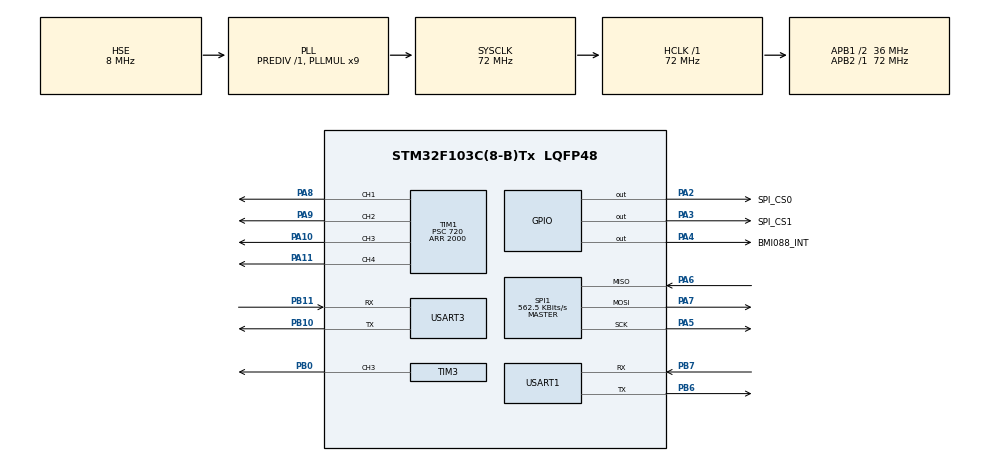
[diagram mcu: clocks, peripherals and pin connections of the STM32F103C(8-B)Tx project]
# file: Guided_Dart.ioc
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Dma.Request0=USART1_RX
Dma.Request1=USART1_TX
Dma.Request2=USART3_RX
Dma.Request3=USART3_TX
Dma.USART1_RX.0.Direction=DMA_PERIPH_TO_MEMORY
Dma.USART1_RX.0.Instance=DMA1_Channel5
Dma.USART1_RX.0.MemDataAlignment=DMA_MDATAALIGN_BYTE
Dma.USART1_RX.0.MemInc=DMA_MINC_ENABLE
Dma.USART1_RX.0.Mode=DMA_NORMAL
Dma.USART1_RX.0.PeriphDataAlignment=DMA_PDATAALIGN_BYTE
Dma.USART1_RX.0.PeriphInc=DMA_PINC_DISABLE
Dma.USART1_RX.0.Priority=DMA_PRIORITY_LOW
Dma.USART1_TX.1.Direction=DMA_MEMORY_TO_PERIPH
Dma.USART1_TX.1.Instance=DMA1_Channel4
Dma.USART1_TX.1.MemDataAlignment=DMA_MDATAALIGN_BYTE
Dma.USART1_TX.1.MemInc=DMA_MINC_ENABLE
Dma.USART1_TX.1.Mode=DMA_NORMAL
Dma.USART1_TX.1.PeriphDataAlignment=DMA_PDATAALIGN_BYTE
Dma.USART1_TX.1.PeriphInc=DMA_PINC_DISABLE
Dma.USART1_TX.1.Priority=DMA_PRIORITY_LOW
Dma.USART3_RX.2.Direction=DMA_PERIPH_TO_MEMORY
Dma.USART3_RX.2.Instance=DMA1_Channel3
Dma.USART3_RX.2.MemDataAlignment=DMA_MDATAALIGN_BYTE
Dma.USART3_RX.2.MemInc=DMA_MINC_ENABLE
Dma.USART3_RX.2.Mode=DMA_NORMAL
Dma.USART3_RX.2.PeriphDataAlignment=DMA_PDATAALIGN_BYTE
Dma.USART3_RX.2.PeriphInc=DMA_PINC_DISABLE
Dma.USART3_RX.2.Priority=DMA_PRIORITY_LOW
Dma.USART3_TX.3.Direction=DMA_MEMORY_TO_PERIPH
Dma.USART3_TX.3.Instance=DMA1_Channel2
Dma.USART3_TX.3.MemDataAlignment=DMA_MDATAALIGN_BYTE
Dma.USART3_TX.3.MemInc=DMA_MINC_ENABLE
Dma.USART3_TX.3.Mode=DMA_NORMAL
Dma.USART3_TX.3.PeriphDataAlignment=DMA_PDATAALIGN_BYTE
Dma.USART3_TX.3.PeriphInc=DMA_PINC_DISABLE
Dma.USART3_TX.3.Priority=DMA_PRIORITY_LOW
Mcu.Family=STM32F1
Mcu.Name=STM32F103C(8-B)Tx
Mcu.Package=LQFP48
NVIC.DMA1_Channel2_IRQn=true\:0\:0\:false\:false\:true\:false\:true\:true
NVIC.DMA1_Channel3_IRQn=true\:0\:0\:false\:false\:true\:false\:true\:true
NVIC.DMA1_Channel4_IRQn=true\:0\:0\:false\:false\:true\:false\:true\:true
NVIC.DMA1_Channel5_IRQn=true\:0\:0\:false\:false\:true\:false\:true\:true
NVIC.PriorityGroup=NVIC_PRIORITYGROUP_4
NVIC.TIM2_IRQn=true\:0\:0\:false\:false\:true\:true\:true\:true
NVIC.USART1_IRQn=true\:1\:0\:true\:false\:true\:true\:true\:true
NVIC.USART3_IRQn=true\:1\:0\:true\:false\:true\:true\:true\:true
PA10.Signal=S_TIM1_CH3
PA11.Signal=S_TIM1_CH4
PA13.Mode=Serial_Wire
PA13.Signal=SYS_JTMS-SWDIO
PA14.Mode=Serial_Wire
PA14.Signal=SYS_JTCK-SWCLK
PA2.GPIO_Label=SPI_CS0
PA2.Signal=GPIO_Output
PA3.GPIO_Label=SPI_CS1
PA3.Signal=GPIO_Output
PA4.GPIO_Label=BMI088_INT
PA4.Signal=GPIO_Output
PA5.Mode=Full_Duplex_Master
PA5.Signal=SPI1_SCK
PA6.Mode=Full_Duplex_Master
PA6.Signal=SPI1_MISO
PA7.Mode=Full_Duplex_Master
PA7.Signal=SPI1_MOSI
PA8.Signal=S_TIM1_CH1
PA9.Signal=S_TIM1_CH2
PB0.Signal=S_TIM3_CH3
PB10.Mode=Asynchronous
PB10.Signal=USART3_TX
PB11.Mode=Asynchronous
PB11.Signal=USART3_RX
PB6.Mode=Asynchronous
PB6.Signal=USART1_TX
PB7.Mode=Asynchronous
PB7.Signal=USART1_RX
PD0-OSC_IN.Mode=HSE-External-Oscillator
PD0-OSC_IN.Signal=RCC_OSC_IN
PD1-OSC_OUT.Mode=HSE-External-Oscillator
PD1-OSC_OUT.Signal=RCC_OSC_OUT
ProjectManager.HeapSize=0x200
ProjectManager.StackSize=0x400
ProjectManager.TargetToolchain=MDK-ARM V5.32
RCC.AHBFreq_Value=72000000
RCC.APB1CLKDivider=RCC_HCLK_DIV2
RCC.APB1Freq_Value=36000000
RCC.APB1TimFreq_Value=72000000
RCC.APB2Freq_Value=72000000
RCC.APB2TimFreq_Value=72000000
RCC.HCLKFreq_Value=72000000
RCC.PLLMUL=RCC_PLL_MUL9
RCC.PLLSourceVirtual=RCC_PLLSOURCE_HSE
RCC.SYSCLKFreq_VALUE=72000000
RCC.SYSCLKSource=RCC_SYSCLKSOURCE_PLLCLK
RCC.USBFreq_Value=72000000
SH.S_TIM1_CH1.0=TIM1_CH1,PWM Generation1 CH1
SH.S_TIM1_CH2.0=TIM1_CH2,PWM Generation2 CH2
SH.S_TIM1_CH3.0=TIM1_CH3,PWM Generation3 CH3
SH.S_TIM1_CH4.0=TIM1_CH4,PWM Generation4 CH4
SH.S_TIM3_CH3.0=TIM3_CH3,PWM Generation3 CH3
SPI1.BaudRatePrescaler=SPI_BAUDRATEPRESCALER_128
SPI1.CLKPhase=SPI_PHASE_2EDGE
SPI1.CLKPolarity=SPI_POLARITY_HIGH
SPI1.CalculateBaudRate=562.5 KBits/s
SPI1.Direction=SPI_DIRECTION_2LINES
SPI1.Mode=SPI_MODE_MASTER
SPI1.VirtualType=VM_MASTER
TIM1.Channel-PWM\ Generation1\ CH1=TIM_CHANNEL_1
TIM1.Channel-PWM\ Generation2\ CH2=TIM_CHANNEL_2
TIM1.Channel-PWM\ Generation3\ CH3=TIM_CHANNEL_3
TIM1.Channel-PWM\ Generation4\ CH4=TIM_CHANNEL_4
TIM1.Period=2000
TIM1.Prescaler=720
TIM2.Period=1000-1
TIM2.Prescaler=720-1
TIM3.Channel-PWM\ Generation3\ CH3=TIM_CHANNEL_3
TIM3.Period=1000
TIM3.Prescaler=720
TIM4.Period=1000-1
TIM4.Prescaler=720-1
USART1.VirtualMode=VM_ASYNC
USART3.VirtualMode=VM_ASYNC
VP_TIM1_VS_ClockSourceINT.Mode=Internal
VP_TIM2_VS_ClockSourceINT.Mode=Internal
VP_TIM3_VS_ClockSourceINT.Mode=Internal
VP_TIM4_VS_ClockSourceINT.Mode=Internal
board=custom

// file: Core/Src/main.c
/* USER CODE BEGIN Header */
/**
  ******************************************************************************
  * @file           : main.c
  * @brief          : Main program body
  ******************************************************************************
  * @attention
  *
  * Copyright (c) 2026 STMicroelectronics.
  * All rights reserved.
  *
  * This software is licensed under terms that can be found in the LICENSE file
  * in the root directory of this software component.
  * If no LICENSE file comes with this software, it is provided AS-IS.
  *
  ******************************************************************************
  */
/* USER CODE END Header */
#include "main.h"
#include "dma.h"
#include "spi.h"
#include "tim.h"
#include "usart.h"
#include "gpio.h"

/* USER CODE BEGIN Includes */
#include "app_task.h"
/* USER CODE END Includes */

void SystemClock_Config(void);

int main(void)
{

  /* MCU Configuration--------------------------------------------------------*/

  /* Reset of all peripherals, Initializes the Flash interface and the Systick. */
  HAL_Init();

  /* Configure the system clock */
  SystemClock_Config();

  /* Initialize all configured peripherals */
  MX_GPIO_Init();
  MX_DMA_Init();
  MX_SPI1_Init();
  MX_TIM1_Init();
  MX_TIM3_Init();
  MX_USART1_UART_Init();
  MX_USART3_UART_Init();
  MX_TIM2_Init();
  MX_TIM4_Init();
  /* USER CODE BEGIN 2 */
  App_Task_Init(); // 初始化任务系统（含飞控初始化和TIM2调度启动�?
  /* USER CODE END 2 */

  /* Infinite loop */
  /* USER CODE BEGIN WHILE */
  while (1)
  {
    Task_Loop(); // 执行时间片轮�?
    /* USER CODE END WHILE */

  }
}

void SystemClock_Config(void)
{
  RCC_OscInitTypeDef RCC_OscInitStruct = {0};
  RCC_ClkInitTypeDef RCC_ClkInitStruct = {0};

  /** Initializes the RCC Oscillators according to the specified parameters
  * in the RCC_OscInitTypeDef structure.
  */
  RCC_OscInitStruct.OscillatorType = RCC_OSCILLATORTYPE_HSE;
  RCC_OscInitStruct.HSEState = RCC_HSE_ON;
  RCC_OscInitStruct.HSEPredivValue = RCC_HSE_PREDIV_DIV1;
  RCC_OscInitStruct.HSIState = RCC_HSI_ON;
  RCC_OscInitStruct.PLL.PLLState = RCC_PLL_ON;
  RCC_OscInitStruct.PLL.PLLSource = RCC_PLLSOURCE_HSE;
  RCC_OscInitStruct.PLL.PLLMUL = RCC_PLL_MUL9;
  if (HAL_RCC_OscConfig(&RCC_OscInitStruct) != HAL_OK)
  {
    Error_Handler();
  }

  /** Initializes the CPU, AHB and APB buses clocks
  */
  RCC_ClkInitStruct.ClockType = RCC_CLOCKTYPE_HCLK|RCC_CLOCKTYPE_SYSCLK
                              |RCC_CLOCKTYPE_PCLK1|RCC_CLOCKTYPE_PCLK2;
  RCC_ClkInitStruct.SYSCLKSource = RCC_SYSCLKSOURCE_PLLCLK;
  RCC_ClkInitStruct.AHBCLKDivider = RCC_SYSCLK_DIV1;
  RCC_ClkInitStruct.APB1CLKDivider = RCC_HCLK_DIV2;
  RCC_ClkInitStruct.APB2CLKDivider = RCC_HCLK_DIV1;

  if (HAL_RCC_ClockConfig(&RCC_ClkInitStruct, FLASH_LATENCY_2) != HAL_OK)
  {
    Error_Handler();
  }
}

/* USER CODE BEGIN 4 */
// HAL_TIM_PeriodElapsedCallback 实现�? app_task.cpp 中，此处不重复定义�??

/* USER CODE END 4 */

void Error_Handler(void)
{
  __disable_irq();
  while (1)
  {
  }
}
